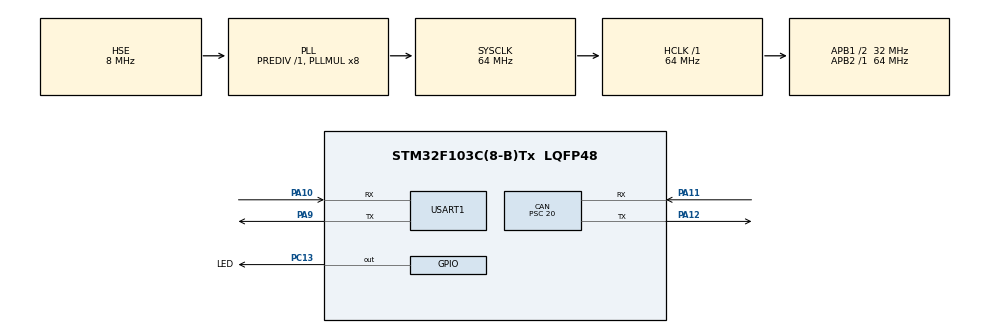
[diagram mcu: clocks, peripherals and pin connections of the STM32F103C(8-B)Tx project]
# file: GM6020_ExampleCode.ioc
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CAN.BS1=CAN_BS1_11TQ
CAN.BS2=CAN_BS2_4TQ
CAN.CalculateBaudRate=100000
CAN.CalculateTimeBit=10000
CAN.CalculateTimeQuantum=625.0
CAN.Mode=CAN_MODE_LOOPBACK
CAN.NART=ENABLE
CAN.Prescaler=20
CAN.TTCM=DISABLE
CAN.TXFP=DISABLE
FREERTOS.Tasks01=MAINTASK,0,256,StartDefaultTask,Default,NULL,Dynamic,NULL,NULL;Serialinput,-3,256,StartTask02,Default,NULL,Dynamic,NULL,NULL;Contorl,3,256,StartTask03,Default,NULL,Dynamic,NULL,NULL
FREERTOS.configENABLE_FPU=1
FREERTOS.configMINIMAL_STACK_SIZE=256
FREERTOS.configTOTAL_HEAP_SIZE=4096
Mcu.Family=STM32F1
Mcu.Name=STM32F103C(8-B)Tx
Mcu.Package=LQFP48
NVIC.CAN1_RX1_IRQn=true\:5\:0\:false\:false\:true\:true\:true\:true\:true
NVIC.PriorityGroup=NVIC_PRIORITYGROUP_4
NVIC.TIM3_IRQn=true\:15\:0\:false\:false\:true\:false\:false\:true\:true
NVIC.TimeBase=TIM3_IRQn
NVIC.TimeBaseIP=TIM3
NVIC.USART1_IRQn=true\:5\:0\:false\:false\:true\:true\:true\:true\:true
NVIC.USB_LP_CAN1_RX0_IRQn=true\:5\:0\:false\:false\:true\:true\:true\:true\:true
PA10.Mode=Asynchronous
PA10.Signal=USART1_RX
PA11.Mode=CAN_Activate
PA11.Signal=CAN_RX
PA12.Mode=CAN_Activate
PA12.Signal=CAN_TX
PA13.Mode=Serial_Wire
PA13.Signal=SYS_JTMS-SWDIO
PA14.Mode=Serial_Wire
PA14.Signal=SYS_JTCK-SWCLK
PA9.Mode=Asynchronous
PA9.Signal=USART1_TX
PC13-TAMPER-RTC.GPIO_Label=LED
PC13-TAMPER-RTC.Signal=GPIO_Output
PD0-OSC_IN.Mode=HSE-External-Oscillator
PD0-OSC_IN.Signal=RCC_OSC_IN
PD1-OSC_OUT.Mode=HSE-External-Oscillator
PD1-OSC_OUT.Signal=RCC_OSC_OUT
ProjectManager.HeapSize=0x200
ProjectManager.StackSize=0x400
ProjectManager.TargetToolchain=CMake
RCC.AHBFreq_Value=64000000
RCC.APB1CLKDivider=RCC_HCLK_DIV2
RCC.APB1Freq_Value=32000000
RCC.APB1TimFreq_Value=64000000
RCC.APB2Freq_Value=64000000
RCC.APB2TimFreq_Value=64000000
RCC.EnbaleCSS=true
RCC.HCLKFreq_Value=64000000
RCC.PLLMUL=RCC_PLL_MUL8
RCC.PLLSourceVirtual=RCC_PLLSOURCE_HSE
RCC.SYSCLKFreq_VALUE=64000000
RCC.SYSCLKSource=RCC_SYSCLKSOURCE_PLLCLK
RCC.USBFreq_Value=64000000
TIM4.Prescaler=64
USART1.VirtualMode=VM_ASYNC
VP_CRC_VS_CRC.Mode=CRC_Activate
VP_FREERTOS_VS_CMSIS_V1.Mode=CMSIS_V1
VP_SYS_VS_tim3.Mode=TIM3
VP_TIM4_VS_ClockSourceINT.Mode=Internal
board=custom

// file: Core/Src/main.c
/* USER CODE BEGIN Header */
/**
 ******************************************************************************
 * @file           : main.c
 * @brief          : Main program body
 ******************************************************************************
 * @attention
 *
 * Copyright (c) 2026 STMicroelectronics.
 * All rights reserved.
 *
 * This software is licensed under terms that can be found in the LICENSE file
 * in the root directory of this software component.
 * If no LICENSE file comes with this software, it is provided AS-IS.
 *
 ******************************************************************************
 */
/* USER CODE END Header */
#include "main.h"
#include "cmsis_os.h"
#include "can.h"
#include "crc.h"
#include "tim.h"
#include "usart.h"
#include "gpio.h"

void SystemClock_Config(void);
void MX_FREERTOS_Init(void);

/* USER CODE BEGIN 0 */
#include "GM6020_HW.h"
#include "PID.h"
#include "UART_IO.h"
#include "stdio.h"
#include "tim.h"
#include "TrueMain.h"
/* USER CODE END 0 */

int main(void)
{

  /* MCU Configuration--------------------------------------------------------*/

  /* Reset of all peripherals, Initializes the Flash interface and the Systick. */
  HAL_Init();

  /* USER CODE BEGIN Init */
  HAL_Delay(10);
  /* USER CODE END Init */

  /* Configure the system clock */
  SystemClock_Config();

  /* Initialize all configured peripherals */
  MX_GPIO_Init();
  MX_CAN_Init();
  MX_USART1_UART_Init();
  MX_CRC_Init();
  MX_TIM4_Init();
  /* USER CODE BEGIN 2 */
  MainSetup();

  /* USER CODE END 2 */

  /* Call init function for freertos objects (in cmsis_os2.c) */
  MX_FREERTOS_Init();

  /* Start scheduler */
  osKernelStart();

  /* We should never get here as control is now taken by the scheduler */

  /* Infinite loop */
    while (1)
    {

    }
}

void SystemClock_Config(void)
{
  RCC_OscInitTypeDef RCC_OscInitStruct = {0};
  RCC_ClkInitTypeDef RCC_ClkInitStruct = {0};

  /** Initializes the RCC Oscillators according to the specified parameters
  * in the RCC_OscInitTypeDef structure.
  */
  RCC_OscInitStruct.OscillatorType = RCC_OSCILLATORTYPE_HSE;
  RCC_OscInitStruct.HSEState = RCC_HSE_ON;
  RCC_OscInitStruct.HSEPredivValue = RCC_HSE_PREDIV_DIV1;
  RCC_OscInitStruct.HSIState = RCC_HSI_ON;
  RCC_OscInitStruct.PLL.PLLState = RCC_PLL_ON;
  RCC_OscInitStruct.PLL.PLLSource = RCC_PLLSOURCE_HSE;
  RCC_OscInitStruct.PLL.PLLMUL = RCC_PLL_MUL8;
  if (HAL_RCC_OscConfig(&RCC_OscInitStruct) != HAL_OK)
  {
    Error_Handler();
  }

  /** Initializes the CPU, AHB and APB buses clocks
  */
  RCC_ClkInitStruct.ClockType = RCC_CLOCKTYPE_HCLK|RCC_CLOCKTYPE_SYSCLK
                              |RCC_CLOCKTYPE_PCLK1|RCC_CLOCKTYPE_PCLK2;
  RCC_ClkInitStruct.SYSCLKSource = RCC_SYSCLKSOURCE_PLLCLK;
  RCC_ClkInitStruct.AHBCLKDivider = RCC_SYSCLK_DIV1;
  RCC_ClkInitStruct.APB1CLKDivider = RCC_HCLK_DIV2;
  RCC_ClkInitStruct.APB2CLKDivider = RCC_HCLK_DIV1;

  if (HAL_RCC_ClockConfig(&RCC_ClkInitStruct, FLASH_LATENCY_2) != HAL_OK)
  {
    Error_Handler();
  }

  /** Enables the Clock Security System
  */
  HAL_RCC_EnableCSS();
}

void HAL_TIM_PeriodElapsedCallback(TIM_HandleTypeDef *htim)
{
  if (htim->Instance == TIM3)
  {
    HAL_IncTick();
  }
}

void Error_Handler(void)
{
    __disable_irq();
    while (1)
    {
    }
}

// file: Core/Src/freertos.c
/* USER CODE BEGIN Header */
/**
 ******************************************************************************
 * File Name          : freertos.c
 * Description        : Code for freertos applications
 ******************************************************************************
 * @attention
 *
 * Copyright (c) 2026 STMicroelectronics.
 * All rights reserved.
 *
 * This software is licensed under terms that can be found in the LICENSE file
 * in the root directory of this software component.
 * If no LICENSE file comes with this software, it is provided AS-IS.
 *
 ******************************************************************************
 */
/* USER CODE END Header */

#include "FreeRTOS.h"
#include "TrueMain.h"
#include "cmsis_os.h"
#include "main.h"
#include "task.h"

/* USER CODE BEGIN Includes */
#include "GM6020_HW.h"
#include "PID.h"
#include "UART_IO.h"

/* USER CODE END Includes */

osThreadId MAINTASKHandle;
osThreadId SerialinputHandle;
osThreadId ContorlHandle;

void StartDefaultTask(void const* argument);
void StartTask02(void const* argument);
void StartTask03(void const* argument);

void MX_FREERTOS_Init(void); /* (MISRA C 2004 rule 8.1) */

/* GetIdleTaskMemory prototype (linked to static allocation support) */
void vApplicationGetIdleTaskMemory(StaticTask_t** ppxIdleTaskTCBBuffer, StackType_t** ppxIdleTaskStackBuffer, uint32_t* pulIdleTaskStackSize);

/* USER CODE BEGIN GET_IDLE_TASK_MEMORY */
static StaticTask_t xIdleTaskTCBBuffer;
static StackType_t xIdleStack[configMINIMAL_STACK_SIZE];

void vApplicationGetIdleTaskMemory(StaticTask_t** ppxIdleTaskTCBBuffer, StackType_t** ppxIdleTaskStackBuffer, uint32_t* pulIdleTaskStackSize)
{
    *ppxIdleTaskTCBBuffer   = &xIdleTaskTCBBuffer;
    *ppxIdleTaskStackBuffer = &xIdleStack[0];
    *pulIdleTaskStackSize   = configMINIMAL_STACK_SIZE;
    /* place for user code */
}
/* USER CODE END GET_IDLE_TASK_MEMORY */

void MX_FREERTOS_Init(void)
{

    /* Create the thread(s) */
    /* definition and creation of MAINTASK */
    osThreadDef(MAINTASK, StartDefaultTask, osPriorityNormal, 0, 256);
    MAINTASKHandle = osThreadCreate(osThread(MAINTASK), NULL);

    /* definition and creation of Serialinput */
    osThreadDef(Serialinput, StartTask02, osPriorityIdle, 0, 256);
    SerialinputHandle = osThreadCreate(osThread(Serialinput), NULL);

    /* definition and creation of Contorl */
    osThreadDef(Contorl, StartTask03, osPriorityRealtime, 0, 256);
    ContorlHandle = osThreadCreate(osThread(Contorl), NULL);

}

/* USER CODE BEGIN Header_StartDefaultTask */

/**
 * @brief  状态灯和串口输出
 * @param  argument: Not used
 * @retval None
 */

/* USER CODE END Header_StartDefaultTask */
void StartDefaultTask(void const* argument)
{
    /* USER CODE BEGIN StartDefaultTask */
    /* Infinite loop */
    MainLoop1();
    /* USER CODE END StartDefaultTask */
}

/* USER CODE BEGIN Header_StartTask02 */
/**
 * @brief 处理串口输入事务
 * @param argument: Not used
 * @retval None
 */
/* USER CODE END Header_StartTask02 */
void StartTask02(void const* argument)
{
    /* USER CODE BEGIN StartTask02 */
    /* Infinite loop */
    MainLoop2();
    /* USER CODE END StartTask02 */
}

/* USER CODE BEGIN Header_StartTask03 */
/**
 * @brief 处理实时事务
 * @param argument: Not used
 * @retval None
 */

/* USER CODE END Header_StartTask03 */
void StartTask03(void const* argument)
{
    /* USER CODE BEGIN StartTask03 */
    /* Infinite loop */
    MainLoop3();
    /* USER CODE END StartTask03 */
}
